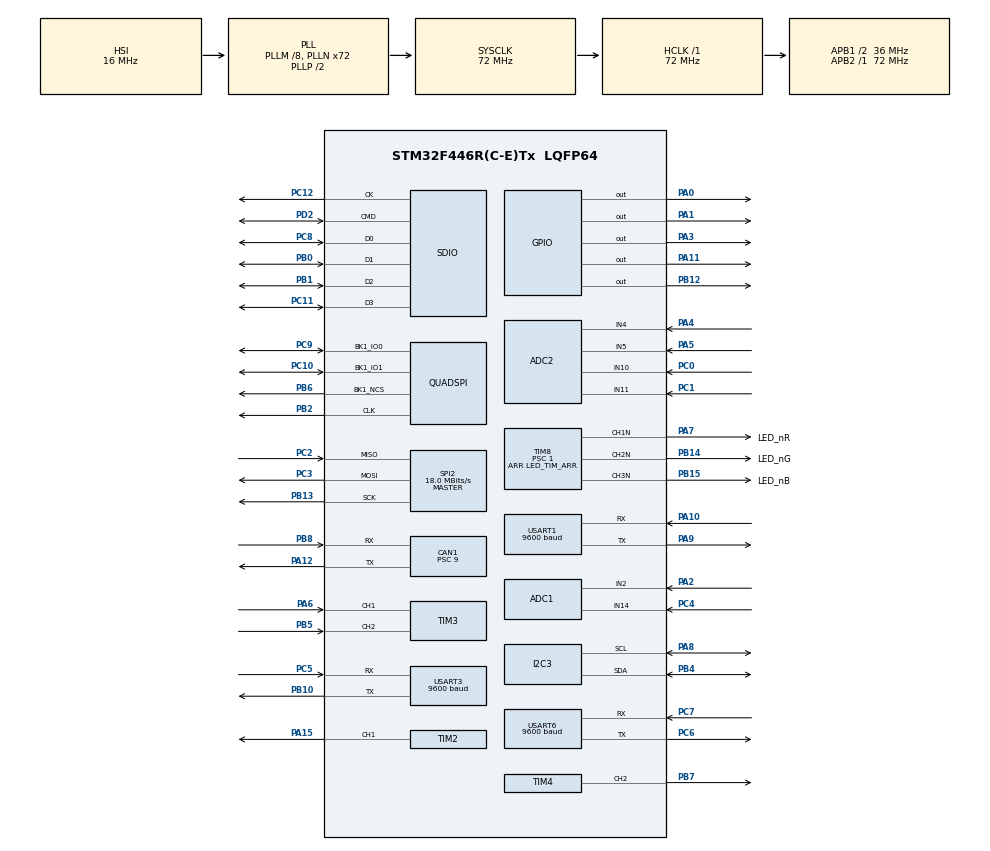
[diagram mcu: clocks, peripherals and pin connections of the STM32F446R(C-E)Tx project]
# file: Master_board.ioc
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ADC1.Channel-95\#ChannelRegularConversion=ADC_CHANNEL_2
ADC1.NbrOfConversionFlag=1
ADC1.Rank-95\#ChannelRegularConversion=1
ADC1.SamplingTime-95\#ChannelRegularConversion=ADC_SAMPLETIME_3CYCLES
ADC1.master=1
ADC2.Channel-88\#ChannelRegularConversion=ADC_CHANNEL_4
ADC2.NbrOfConversionFlag=1
ADC2.Rank-88\#ChannelRegularConversion=1
ADC2.SamplingTime-88\#ChannelRegularConversion=ADC_SAMPLETIME_3CYCLES
CAN1.BS1=CAN_BS1_13TQ
CAN1.BS2=CAN_BS2_2TQ
CAN1.CalculateTimeQuantum=250.0
CAN1.Prescaler=9
Dma.I2C3_RX.2.Direction=DMA_PERIPH_TO_MEMORY
Dma.I2C3_RX.2.FIFOMode=DMA_FIFOMODE_DISABLE
Dma.I2C3_RX.2.Instance=DMA1_Stream2
Dma.I2C3_RX.2.MemDataAlignment=DMA_MDATAALIGN_BYTE
Dma.I2C3_RX.2.MemInc=DMA_MINC_ENABLE
Dma.I2C3_RX.2.Mode=DMA_NORMAL
Dma.I2C3_RX.2.PeriphDataAlignment=DMA_PDATAALIGN_BYTE
Dma.I2C3_RX.2.PeriphInc=DMA_PINC_DISABLE
Dma.I2C3_RX.2.Priority=DMA_PRIORITY_LOW
Dma.Request0=SDIO_RX
Dma.Request1=SDIO_TX
Dma.Request2=I2C3_RX
Dma.Request3=USART3_RX
Dma.Request4=USART3_TX
Dma.Request5=USART1_TX
Dma.SDIO_RX.0.Direction=DMA_PERIPH_TO_MEMORY
Dma.SDIO_RX.0.FIFOMode=DMA_FIFOMODE_ENABLE
Dma.SDIO_RX.0.FIFOThreshold=DMA_FIFO_THRESHOLD_FULL
Dma.SDIO_RX.0.Instance=DMA2_Stream6
Dma.SDIO_RX.0.MemBurst=DMA_MBURST_INC4
Dma.SDIO_RX.0.MemDataAlignment=DMA_MDATAALIGN_WORD
Dma.SDIO_RX.0.MemInc=DMA_MINC_ENABLE
Dma.SDIO_RX.0.Mode=DMA_PFCTRL
Dma.SDIO_RX.0.PeriphBurst=DMA_PBURST_INC4
Dma.SDIO_RX.0.PeriphDataAlignment=DMA_PDATAALIGN_WORD
Dma.SDIO_RX.0.PeriphInc=DMA_PINC_DISABLE
Dma.SDIO_RX.0.Priority=DMA_PRIORITY_LOW
Dma.SDIO_TX.1.Direction=DMA_MEMORY_TO_PERIPH
Dma.SDIO_TX.1.FIFOMode=DMA_FIFOMODE_ENABLE
Dma.SDIO_TX.1.FIFOThreshold=DMA_FIFO_THRESHOLD_FULL
Dma.SDIO_TX.1.Instance=DMA2_Stream3
Dma.SDIO_TX.1.MemBurst=DMA_MBURST_INC4
Dma.SDIO_TX.1.MemDataAlignment=DMA_MDATAALIGN_WORD
Dma.SDIO_TX.1.MemInc=DMA_MINC_ENABLE
Dma.SDIO_TX.1.Mode=DMA_PFCTRL
Dma.SDIO_TX.1.PeriphBurst=DMA_PBURST_INC4
Dma.SDIO_TX.1.PeriphDataAlignment=DMA_PDATAALIGN_WORD
Dma.SDIO_TX.1.PeriphInc=DMA_PINC_DISABLE
Dma.SDIO_TX.1.Priority=DMA_PRIORITY_LOW
Dma.USART1_TX.5.Direction=DMA_MEMORY_TO_PERIPH
Dma.USART1_TX.5.FIFOMode=DMA_FIFOMODE_DISABLE
Dma.USART1_TX.5.Instance=DMA2_Stream7
Dma.USART1_TX.5.MemDataAlignment=DMA_MDATAALIGN_BYTE
Dma.USART1_TX.5.MemInc=DMA_MINC_ENABLE
Dma.USART1_TX.5.Mode=DMA_NORMAL
Dma.USART1_TX.5.PeriphDataAlignment=DMA_PDATAALIGN_BYTE
Dma.USART1_TX.5.PeriphInc=DMA_PINC_DISABLE
Dma.USART1_TX.5.Priority=DMA_PRIORITY_LOW
Dma.USART3_RX.3.Direction=DMA_PERIPH_TO_MEMORY
Dma.USART3_RX.3.FIFOMode=DMA_FIFOMODE_DISABLE
Dma.USART3_RX.3.Instance=DMA1_Stream1
Dma.USART3_RX.3.MemDataAlignment=DMA_MDATAALIGN_BYTE
Dma.USART3_RX.3.MemInc=DMA_MINC_ENABLE
Dma.USART3_RX.3.Mode=DMA_NORMAL
Dma.USART3_RX.3.PeriphDataAlignment=DMA_PDATAALIGN_BYTE
Dma.USART3_RX.3.PeriphInc=DMA_PINC_DISABLE
Dma.USART3_RX.3.Priority=DMA_PRIORITY_LOW
Dma.USART3_TX.4.Direction=DMA_MEMORY_TO_PERIPH
Dma.USART3_TX.4.FIFOMode=DMA_FIFOMODE_DISABLE
Dma.USART3_TX.4.Instance=DMA1_Stream4
Dma.USART3_TX.4.MemDataAlignment=DMA_MDATAALIGN_BYTE
Dma.USART3_TX.4.MemInc=DMA_MINC_ENABLE
Dma.USART3_TX.4.Mode=DMA_NORMAL
Dma.USART3_TX.4.PeriphDataAlignment=DMA_PDATAALIGN_BYTE
Dma.USART3_TX.4.PeriphInc=DMA_PINC_DISABLE
Dma.USART3_TX.4.Priority=DMA_PRIORITY_LOW
FATFS._FS_LOCK=2
FATFS._USE_STRFUNC=0
FREERTOS.Tasks01=defaultTask,0,256,StartDefaultTask,Default,NULL,Dynamic,NULL,NULL;task_s1,0,256,TK_task_s1,Default,NULL,Dynamic,NULL,NULL;task_s2,0,256,TK_task_s2,Default,NULL,Dynamic,NULL,NULL
FREERTOS.configMINIMAL_STACK_SIZE=256
FREERTOS.configTOTAL_HEAP_SIZE=64400
Mcu.Family=STM32F4
Mcu.Name=STM32F446R(C-E)Tx
Mcu.Package=LQFP64
Mcu.UserConstants=LED_TIM_ARR,1000
NVIC.DMA1_Stream1_IRQn=true\:5\:0\:false\:false\:true\:true\:false
NVIC.DMA1_Stream2_IRQn=true\:5\:0\:false\:false\:true\:true\:false
NVIC.DMA1_Stream4_IRQn=true\:5\:0\:false\:false\:true\:true\:false
NVIC.DMA2_Stream3_IRQn=true\:5\:0\:false\:false\:true\:true\:false
NVIC.DMA2_Stream6_IRQn=true\:5\:0\:false\:false\:true\:true\:false
NVIC.DMA2_Stream7_IRQn=true\:5\:0\:false\:false\:true\:true\:false
NVIC.PriorityGroup=NVIC_PRIORITYGROUP_4
NVIC.SDIO_IRQn=true\:5\:0\:false\:false\:true\:true\:true
NVIC.TIM8_TRG_COM_TIM14_IRQn=true\:0\:0\:false\:false\:true\:false\:false
NVIC.TimeBase=TIM8_TRG_COM_TIM14_IRQn
NVIC.TimeBaseIP=TIM14
NVIC.USART1_IRQn=true\:5\:0\:false\:false\:true\:true\:true
PA0-WKUP.Signal=GPIO_Output
PA1.Signal=GPIO_Output
PA10.Mode=Asynchronous
PA10.Signal=USART1_RX
PA11.Signal=GPIO_Output
PA12.Mode=Master
PA12.Signal=CAN1_TX
PA13.Mode=Trace_Asynchronous_SW
PA13.Signal=SYS_JTMS-SWDIO
PA14.Mode=Trace_Asynchronous_SW
PA14.Signal=SYS_JTCK-SWCLK
PA15.Signal=S_TIM2_CH1_ETR
PA2.Signal=ADCx_IN2
PA3.Signal=GPIO_Output
PA4.Signal=ADCx_IN4
PA5.Signal=ADCx_IN5
PA6.Signal=S_TIM3_CH1
PA7.GPIO_Label=LED_nR
PA7.Mode=PWM Generation1 CH1N
PA7.Signal=TIM8_CH1N
PA8.Mode=I2C
PA8.Signal=I2C3_SCL
PA9.Mode=Asynchronous
PA9.Signal=USART1_TX
PB0.Mode=SD_4_bits_Wide_bus
PB0.Signal=SDIO_D1
PB1.Mode=SD_4_bits_Wide_bus
PB1.Signal=SDIO_D2
PB10.Mode=Asynchronous
PB10.Signal=USART3_TX
PB12.Signal=GPIO_Output
PB13.Mode=Full_Duplex_Master
PB13.Signal=SPI2_SCK
PB14.GPIO_Label=LED_nG
PB14.Mode=PWM Generation2 CH2N
PB14.Signal=TIM8_CH2N
PB15.GPIO_Label=LED_nB
PB15.Mode=PWM Generation3 CH3N
PB15.Signal=TIM8_CH3N
PB2.Mode=Single Bank 1 2IOs
PB2.Signal=QUADSPI_CLK
PB3.Mode=Trace_Asynchronous_SW
PB3.Signal=SYS_JTDO-SWO
PB4.Mode=I2C
PB4.Signal=I2C3_SDA
PB5.Signal=S_TIM3_CH2
PB6.Mode=Single Bank 1 2IOs
PB6.Signal=QUADSPI_BK1_NCS
PB7.Signal=S_TIM4_CH2
PB8.Mode=Master
PB8.Signal=CAN1_RX
PC0.Signal=ADCx_IN10
PC1.Signal=ADCx_IN11
PC10.Mode=Single Bank 1 2IOs
PC10.Signal=QUADSPI_BK1_IO1
PC11.Mode=SD_4_bits_Wide_bus
PC11.Signal=SDIO_D3
PC12.Mode=SD_4_bits_Wide_bus
PC12.Signal=SDIO_CK
PC14-OSC32_IN.Mode=LSE-External-Oscillator
PC14-OSC32_IN.Signal=RCC_OSC32_IN
PC15-OSC32_OUT.Mode=LSE-External-Oscillator
PC15-OSC32_OUT.Signal=RCC_OSC32_OUT
PC2.Mode=Full_Duplex_Master
PC2.Signal=SPI2_MISO
PC3.Mode=Full_Duplex_Master
PC3.Signal=SPI2_MOSI
PC4.Signal=ADCx_IN14
PC5.Mode=Asynchronous
PC5.Signal=USART3_RX
PC6.Mode=Asynchronous
PC6.Signal=USART6_TX
PC7.Mode=Asynchronous
PC7.Signal=USART6_RX
PC8.Mode=SD_4_bits_Wide_bus
PC8.Signal=SDIO_D0
PC9.Mode=Single Bank 1 2IOs
PC9.Signal=QUADSPI_BK1_IO0
PD2.Mode=SD_4_bits_Wide_bus
PD2.Signal=SDIO_CMD
PH0-OSC_IN.Mode=HSE-External-Oscillator
PH0-OSC_IN.Signal=RCC_OSC_IN
PH1-OSC_OUT.Mode=HSE-External-Oscillator
PH1-OSC_OUT.Signal=RCC_OSC_OUT
ProjectManager.HeapSize=0x200
ProjectManager.StackSize=0x400
ProjectManager.TargetToolchain=SW4STM32
RCC.AHBFreq_Value=72000000
RCC.APB1CLKDivider=RCC_HCLK_DIV2
RCC.APB1Freq_Value=36000000
RCC.APB1TimFreq_Value=72000000
RCC.APB2Freq_Value=72000000
RCC.APB2TimFreq_Value=72000000
RCC.CortexFreq_Value=72000000
RCC.HCLKFreq_Value=72000000
RCC.HSE_VALUE=8000000
RCC.PLLM=8
RCC.PLLN=72
RCC.PLLQ=3
RCC.SYSCLKFreq_VALUE=72000000
RCC.SYSCLKSource=RCC_SYSCLKSOURCE_PLLCLK
RCC.USBFreq_Value=48000000
RCC.VCOOutputFreq_Value=144000000
SH.ADCx_IN10.0=ADC2_IN10,IN10
SH.ADCx_IN11.0=ADC2_IN11,IN11
SH.ADCx_IN14.0=ADC1_IN14,IN14
SH.ADCx_IN2.0=ADC1_IN2,IN2
SH.ADCx_IN4.0=ADC2_IN4,IN4
SH.ADCx_IN5.0=ADC2_IN5,IN5
SH.S_TIM2_CH1_ETR.0=TIM2_CH1,Output Compare1 CH1
SH.S_TIM3_CH1.0=TIM3_CH1,TriggerSource_TI1FP1
SH.S_TIM3_CH2.0=TIM3_CH2,Input_Capture2_from_TI2
SH.S_TIM4_CH2.0=TIM4_CH2,Output Compare2 CH2
SPI2.BaudRatePrescaler=SPI_BAUDRATEPRESCALER_2
SPI2.CalculateBaudRate=18.0 MBits/s
SPI2.Direction=SPI_DIRECTION_2LINES
SPI2.Mode=SPI_MODE_MASTER
SPI2.VirtualType=VM_MASTER
TIM2.Channel-Output\ Compare1\ CH1=TIM_CHANNEL_1
TIM3.Channel-Input_Capture2_from_TI2=TIM_CHANNEL_2
TIM4.Channel-Output\ Compare2\ CH2=TIM_CHANNEL_2
TIM8.Channel-PWM\ Generation1\ CH1N=TIM_CHANNEL_1
TIM8.Channel-PWM\ Generation2\ CH2N=TIM_CHANNEL_2
TIM8.Channel-PWM\ Generation3\ CH3N=TIM_CHANNEL_3
TIM8.OCMode_PWM-PWM\ Generation1\ CH1N=TIM_OCMODE_PWM2
TIM8.OCMode_PWM-PWM\ Generation2\ CH2N=TIM_OCMODE_PWM2
TIM8.OCMode_PWM-PWM\ Generation3\ CH3N=TIM_OCMODE_PWM2
TIM8.Period=LED_TIM_ARR
TIM8.Prescaler=1
USART1.BaudRate=9600
USART1.VirtualMode=VM_ASYNC
USART3.BaudRate=9600
USART3.VirtualMode=VM_ASYNC
USART6.BaudRate=9600
USART6.VirtualMode=VM_ASYNC
VP_FATFS_VS_SDIO.Mode=SDIO
VP_FREERTOS_VS_ENABLE.Mode=Enabled
VP_SYS_VS_tim14.Mode=TIM14
VP_TIM1_VS_ClockSourceINT.Mode=Internal
VP_TIM2_VS_ClockSourceINT.Mode=Internal
VP_TIM3_VS_ControllerModeClock.Mode=Clock Mode
VP_TIM4_VS_ClockSourceINT.Mode=Internal
VP_TIM5_VS_ClockSourceINT.Mode=Internal
VP_TIM8_VS_ClockSourceINT.Mode=Internal
board=custom

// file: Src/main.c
/* USER CODE BEGIN Header */
/**
  ******************************************************************************
  * @file           : main.c
  * @brief          : Main program body
  ******************************************************************************
  * This notice applies to any and all portions of this file
  * that are not between comment pairs USER CODE BEGIN and
  * USER CODE END. Other portions of this file, whether
  * inserted by the user or by software development tools
  * are owned by their respective copyright owners.
  *
  * Copyright (c) 2019 STMicroelectronics International N.V.
  * All rights reserved.
  *
  * Redistribution and use in source and binary forms, with or without
  * modification, are permitted, provided that the following conditions are met:
  *
  * 1. Redistribution of source code must retain the above copyright notice,
  *    this list of conditions and the following disclaimer.
  * 2. Redistributions in binary form must reproduce the above copyright notice,
  *    this list of conditions and the following disclaimer in the documentation
  *    and/or other materials provided with the distribution.
  * 3. Neither the name of STMicroelectronics nor the names of other
  *    contributors to this software may be used to endorse or promote products
  *    derived from this software without specific written permission.
  * 4. This software, including modifications and/or derivative works of this
  *    software, must execute solely and exclusively on microcontroller or
  *    microprocessor devices manufactured by or for STMicroelectronics.
  * 5. Redistribution and use of this software other than as permitted under
  *    this license is void and will automatically terminate your rights under
  *    this license.
  *
  * THIS SOFTWARE IS PROVIDED BY STMICROELECTRONICS AND CONTRIBUTORS "AS IS"
  * AND ANY EXPRESS, IMPLIED OR STATUTORY WARRANTIES, INCLUDING, BUT NOT
  * LIMITED TO, THE IMPLIED WARRANTIES OF MERCHANTABILITY, FITNESS FOR A
  * PARTICULAR PURPOSE AND NON-INFRINGEMENT OF THIRD PARTY INTELLECTUAL PROPERTY
  * RIGHTS ARE DISCLAIMED TO THE FULLEST EXTENT PERMITTED BY LAW. IN NO EVENT
  * SHALL STMICROELECTRONICS OR CONTRIBUTORS BE LIABLE FOR ANY DIRECT, INDIRECT,
  * INCIDENTAL, SPECIAL, EXEMPLARY, OR CONSEQUENTIAL DAMAGES (INCLUDING, BUT NOT
  * LIMITED TO, PROCUREMENT OF SUBSTITUTE GOODS OR SERVICES; LOSS OF USE, DATA,
  * OR PROFITS; OR BUSINESS INTERRUPTION) HOWEVER CAUSED AND ON ANY THEORY OF
  * LIABILITY, WHETHER IN CONTRACT, STRICT LIABILITY, OR TORT (INCLUDING
  * NEGLIGENCE OR OTHERWISE) ARISING IN ANY WAY OUT OF THE USE OF THIS SOFTWARE,
  * EVEN IF ADVISED OF THE POSSIBILITY OF SUCH DAMAGE.
  *
  ******************************************************************************
  */
/* USER CODE END Header */

#include "main.h"
#include "cmsis_os.h"
#include "adc.h"
#include "can.h"
#include "dma.h"
#include "fatfs.h"
#include "i2c.h"
#include "quadspi.h"
#include "sdio.h"
#include "spi.h"
#include "tim.h"
#include "usart.h"
#include "gpio.h"

/* USER CODE BEGIN Includes */
#include "led.h"
#include "Status_panel.h"
#include "CAN_communication.h"
/* USER CODE END Includes */

void SystemClock_Config(void);
void MX_FREERTOS_Init(void);

int main(void)
{

  /* MCU Configuration--------------------------------------------------------*/

  /* Reset of all peripherals, Initializes the Flash interface and the Systick. */
  HAL_Init();

  /* Configure the system clock */
  SystemClock_Config();

  /* Initialize all configured peripherals */
  MX_GPIO_Init();
  MX_DMA_Init();
  MX_ADC1_Init();
  MX_ADC2_Init();
  MX_CAN1_Init();
  MX_I2C3_Init();
  MX_QUADSPI_Init();
  MX_SDIO_SD_Init();
  MX_SPI2_Init();
  MX_TIM1_Init();
  MX_TIM2_Init();
  MX_TIM3_Init();
  MX_TIM4_Init();
  MX_TIM5_Init();
  MX_TIM8_Init();
  MX_USART1_UART_Init();
  MX_USART3_UART_Init();
  MX_USART6_UART_Init();
  /* USER CODE BEGIN 2 */

  led_init();
  Status_panel_init(1);

  int i = 0;
  for(i = 0; i<4; i++)
  {
	  setLedPanel(i);
  }
  //CAN_Config(0);

  /* USER CODE END 2 */

  /* Call init function for freertos objects (in freertos.c) */
  MX_FREERTOS_Init();

  /* Start scheduler */
  osKernelStart();

  /* We should never get here as control is now taken by the scheduler */

  /* Infinite loop */
  while (1)
  {

  }
}

void SystemClock_Config(void)
{
  RCC_OscInitTypeDef RCC_OscInitStruct = {0};
  RCC_ClkInitTypeDef RCC_ClkInitStruct = {0};
  RCC_PeriphCLKInitTypeDef PeriphClkInitStruct = {0};

  /**Configure the main internal regulator output voltage
  */
  __HAL_RCC_PWR_CLK_ENABLE();
  __HAL_PWR_VOLTAGESCALING_CONFIG(PWR_REGULATOR_VOLTAGE_SCALE3);
  /**Initializes the CPU, AHB and APB busses clocks
  */
  RCC_OscInitStruct.OscillatorType = RCC_OSCILLATORTYPE_HSI;
  RCC_OscInitStruct.HSIState = RCC_HSI_ON;
  RCC_OscInitStruct.HSICalibrationValue = RCC_HSICALIBRATION_DEFAULT;
  RCC_OscInitStruct.PLL.PLLState = RCC_PLL_ON;
  RCC_OscInitStruct.PLL.PLLSource = RCC_PLLSOURCE_HSI;
  RCC_OscInitStruct.PLL.PLLM = 8;
  RCC_OscInitStruct.PLL.PLLN = 72;
  RCC_OscInitStruct.PLL.PLLP = RCC_PLLP_DIV2;
  RCC_OscInitStruct.PLL.PLLQ = 3;
  RCC_OscInitStruct.PLL.PLLR = 2;
  if (HAL_RCC_OscConfig(&RCC_OscInitStruct) != HAL_OK)
  {
    Error_Handler();
  }
  /**Initializes the CPU, AHB and APB busses clocks
  */
  RCC_ClkInitStruct.ClockType = RCC_CLOCKTYPE_HCLK|RCC_CLOCKTYPE_SYSCLK
                              |RCC_CLOCKTYPE_PCLK1|RCC_CLOCKTYPE_PCLK2;
  RCC_ClkInitStruct.SYSCLKSource = RCC_SYSCLKSOURCE_PLLCLK;
  RCC_ClkInitStruct.AHBCLKDivider = RCC_SYSCLK_DIV1;
  RCC_ClkInitStruct.APB1CLKDivider = RCC_HCLK_DIV2;
  RCC_ClkInitStruct.APB2CLKDivider = RCC_HCLK_DIV1;

  if (HAL_RCC_ClockConfig(&RCC_ClkInitStruct, FLASH_LATENCY_2) != HAL_OK)
  {
    Error_Handler();
  }
  PeriphClkInitStruct.PeriphClockSelection = RCC_PERIPHCLK_SDIO|RCC_PERIPHCLK_CLK48;
  PeriphClkInitStruct.Clk48ClockSelection = RCC_CLK48CLKSOURCE_PLLQ;
  PeriphClkInitStruct.SdioClockSelection = RCC_SDIOCLKSOURCE_CLK48;
  if (HAL_RCCEx_PeriphCLKConfig(&PeriphClkInitStruct) != HAL_OK)
  {
    Error_Handler();
  }
}

void HAL_TIM_PeriodElapsedCallback(TIM_HandleTypeDef *htim)
{
  if (htim->Instance == TIM14) {
    HAL_IncTick();
  }
}

void Error_Handler(void)
{
}

/************************ (C) COPYRIGHT STMicroelectronics *****END OF FILE****/
